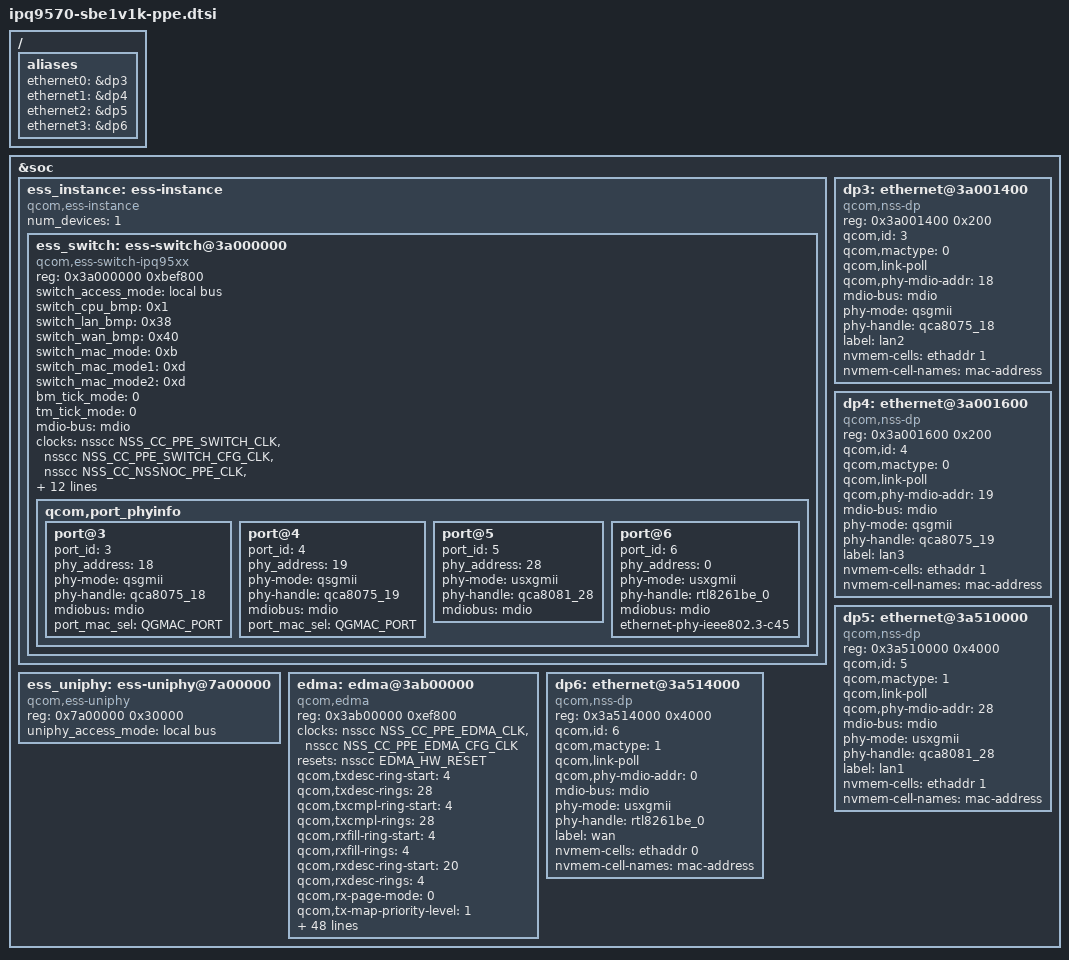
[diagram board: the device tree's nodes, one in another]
// SPDX-License-Identifier: (GPL-2.0+ OR BSD-3-Clause)
/*
 * Qualcomm QSDK14 SSDK/NSS-DP/PPE data path for the Askey SBE1V1K.
 *
 * This is intentionally separate from the board DTS so the upstream PPE
 * data path remains easy to restore while the vendor acceleration stack is
 * being validated on hardware.
 */

/ {
	aliases {
		ethernet0 = &dp3;
		ethernet1 = &dp4;
		ethernet2 = &dp5;
		ethernet3 = &dp6;
	};
};

&soc {
		ess_instance: ess-instance {
			compatible = "qcom,ess-instance";
			num_devices = <1>;
			#address-cells = <1>;
			#size-cells = <1>;

			ess_switch: ess-switch@3a000000 {
				compatible = "qcom,ess-switch-ipq95xx";
				reg = <0x3a000000 0xbef800>;
				switch_access_mode = "local bus";
				switch_cpu_bmp = <0x1>;
				switch_lan_bmp = <0x38>;
				switch_wan_bmp = <0x40>;
				switch_mac_mode = <0xb>;
				switch_mac_mode1 = <0xd>;
				switch_mac_mode2 = <0xd>;
				bm_tick_mode = <0>;
				tm_tick_mode = <0>;
				mdio-bus = <&mdio>;

				clocks = <&nsscc NSS_CC_PPE_SWITCH_CLK>,
					 <&nsscc NSS_CC_PPE_SWITCH_CFG_CLK>,
					 <&nsscc NSS_CC_NSSNOC_PPE_CLK>,
					 <&nsscc NSS_CC_NSSNOC_PPE_CFG_CLK>,
					 <&nsscc NSS_CC_PPE_EDMA_CLK>,
					 <&nsscc NSS_CC_PPE_EDMA_CFG_CLK>,
					 <&nsscc NSS_CC_PPE_SWITCH_IPE_CLK>,
					 <&nsscc NSS_CC_PPE_SWITCH_BTQ_CLK>,
					 <&nsscc NSS_CC_PORT1_MAC_CLK>,
					 <&nsscc NSS_CC_PORT2_MAC_CLK>,
					 <&nsscc NSS_CC_PORT3_MAC_CLK>,
					 <&nsscc NSS_CC_PORT4_MAC_CLK>,
					 <&nsscc NSS_CC_PORT5_MAC_CLK>,
					 <&nsscc NSS_CC_PORT6_MAC_CLK>;
				clock-names = "nss_ppe_clk",
					      "nss_ppe_cfg_clk",
					      "nssnoc_ppe_clk",
					      "nssnoc_ppe_cfg_clk",
					      "nss_edma_clk",
					      "nss_edma_cfg_clk",
					      "nss_ppe_ipe_clk",
					      "nss_ppe_btq_clk",
					      "port1_mac_clk",
					      "port2_mac_clk",
					      "port3_mac_clk",
					      "port4_mac_clk",
					      "port5_mac_clk",
					      "port6_mac_clk";
				resets = <&nsscc PPE_FULL_RESET>;
				reset-names = "ppe_rst";

				qcom,port_phyinfo {
					port@3 {
						port_id = <3>;
						phy_address = <18>;
						phy-mode = "qsgmii";
						phy-handle = <&qca8075_18>;
						mdiobus = <&mdio>;
						port_mac_sel = "QGMAC_PORT";
					};

					port@4 {
						port_id = <4>;
						phy_address = <19>;
						phy-mode = "qsgmii";
						phy-handle = <&qca8075_19>;
						mdiobus = <&mdio>;
						port_mac_sel = "QGMAC_PORT";
					};

					port@5 {
						port_id = <5>;
						phy_address = <28>;
						phy-mode = "usxgmii";
						phy-handle = <&qca8081_28>;
						mdiobus = <&mdio>;
					};

					port@6 {
						port_id = <6>;
						phy_address = <0>;
						phy-mode = "usxgmii";
						phy-handle = <&rtl8261be_0>;
						mdiobus = <&mdio>;
						ethernet-phy-ieee802.3-c45;
					};
				};
			};
		};

		ess_uniphy: ess-uniphy@7a00000 {
			compatible = "qcom,ess-uniphy";
			reg = <0x7a00000 0x30000>;
			uniphy_access_mode = "local bus";
		};

		edma: edma@3ab00000 {
			compatible = "qcom,edma";
			reg = <0x3ab00000 0xef800>;
			reg-names = "edma-reg-base";

			clocks = <&nsscc NSS_CC_PPE_EDMA_CLK>,
				 <&nsscc NSS_CC_PPE_EDMA_CFG_CLK>;
			clock-names = "nss-edma-clk",
				      "nss-edma-cfg-clk";
			resets = <&nsscc EDMA_HW_RESET>;
			reset-names = "edma_rst";

			qcom,txdesc-ring-start = <4>;
			qcom,txdesc-rings = <28>;
			qcom,txcmpl-ring-start = <4>;
			qcom,txcmpl-rings = <28>;
			qcom,rxfill-ring-start = <4>;
			qcom,rxfill-rings = <4>;
			qcom,rxdesc-ring-start = <20>;
			qcom,rxdesc-rings = <4>;
			qcom,rx-page-mode = <0>;
			qcom,tx-map-priority-level = <1>;
			qcom,rx-map-priority-level = <1>;
			qcom,txdesc-map = <8 9 10 11>,
					  <12 13 14 15>,
					  <16 17 18 19>,
					  <20 21 22 23>,
					  <24 25 26 27>,
					  <28 29 30 31>,
					  <4 5 6 7>;
			qcom,txdesc-fc-grp-map = <1 2 3 4 5 6>;
			qcom,rxfill-map = <4 5 6 7>;
			qcom,rxdesc-map = <20 21 22 23>;
			qcom,rx-ring-queue-map = <0 8 16 24>,
						 <1 9 17 25>,
						 <2 10 18 26>,
						 <3 11 19 27>,
						 <4 12 20 28>,
						 <5 13 21 29>,
						 <6 14 22 30>,
						 <7 15 23 31>;
			qcom,vp-id = <8>;

			interrupts = <GIC_SPI 367 IRQ_TYPE_LEVEL_HIGH>,
				     <GIC_SPI 368 IRQ_TYPE_LEVEL_HIGH>,
				     <GIC_SPI 369 IRQ_TYPE_LEVEL_HIGH>,
				     <GIC_SPI 370 IRQ_TYPE_LEVEL_HIGH>,
				     <GIC_SPI 371 IRQ_TYPE_LEVEL_HIGH>,
				     <GIC_SPI 372 IRQ_TYPE_LEVEL_HIGH>,
				     <GIC_SPI 373 IRQ_TYPE_LEVEL_HIGH>,
				     <GIC_SPI 374 IRQ_TYPE_LEVEL_HIGH>,
				     <GIC_SPI 375 IRQ_TYPE_LEVEL_HIGH>,
				     <GIC_SPI 376 IRQ_TYPE_LEVEL_HIGH>,
				     <GIC_SPI 377 IRQ_TYPE_LEVEL_HIGH>,
				     <GIC_SPI 378 IRQ_TYPE_LEVEL_HIGH>,
				     <GIC_SPI 379 IRQ_TYPE_LEVEL_HIGH>,
				     <GIC_SPI 380 IRQ_TYPE_LEVEL_HIGH>,
				     <GIC_SPI 381 IRQ_TYPE_LEVEL_HIGH>,
				     <GIC_SPI 382 IRQ_TYPE_LEVEL_HIGH>,
				     <GIC_SPI 383 IRQ_TYPE_LEVEL_HIGH>,
				     <GIC_SPI 384 IRQ_TYPE_LEVEL_HIGH>,
				     <GIC_SPI 509 IRQ_TYPE_LEVEL_HIGH>,
				     <GIC_SPI 508 IRQ_TYPE_LEVEL_HIGH>,
				     <GIC_SPI 507 IRQ_TYPE_LEVEL_HIGH>,
				     <GIC_SPI 506 IRQ_TYPE_LEVEL_HIGH>,
				     <GIC_SPI 505 IRQ_TYPE_LEVEL_HIGH>,
				     <GIC_SPI 504 IRQ_TYPE_LEVEL_HIGH>,
				     <GIC_SPI 503 IRQ_TYPE_LEVEL_HIGH>,
				     <GIC_SPI 502 IRQ_TYPE_LEVEL_HIGH>,
				     <GIC_SPI 501 IRQ_TYPE_LEVEL_HIGH>,
				     <GIC_SPI 500 IRQ_TYPE_LEVEL_HIGH>,
				     <GIC_SPI 351 IRQ_TYPE_LEVEL_HIGH>,
				     <GIC_SPI 352 IRQ_TYPE_LEVEL_HIGH>,
				     <GIC_SPI 353 IRQ_TYPE_LEVEL_HIGH>,
				     <GIC_SPI 354 IRQ_TYPE_LEVEL_HIGH>,
				     <GIC_SPI 499 IRQ_TYPE_LEVEL_HIGH>,
				     <GIC_SPI 359 IRQ_TYPE_LEVEL_HIGH>,
				     <GIC_SPI 360 IRQ_TYPE_LEVEL_HIGH>,
				     <GIC_SPI 361 IRQ_TYPE_LEVEL_HIGH>,
				     <GIC_SPI 362 IRQ_TYPE_LEVEL_HIGH>;
		};

		dp3: ethernet@3a001400 {
			compatible = "qcom,nss-dp";
			reg = <0x3a001400 0x200>;
			qcom,id = <3>;
			qcom,mactype = <0>;
			qcom,link-poll;
			qcom,phy-mdio-addr = <18>;
			mdio-bus = <&mdio>;
			phy-mode = "qsgmii";
			phy-handle = <&qca8075_18>;
			label = "lan2";
			nvmem-cells = <&ethaddr 1>;
			nvmem-cell-names = "mac-address";
		};

		dp4: ethernet@3a001600 {
			compatible = "qcom,nss-dp";
			reg = <0x3a001600 0x200>;
			qcom,id = <4>;
			qcom,mactype = <0>;
			qcom,link-poll;
			qcom,phy-mdio-addr = <19>;
			mdio-bus = <&mdio>;
			phy-mode = "qsgmii";
			phy-handle = <&qca8075_19>;
			label = "lan3";
			nvmem-cells = <&ethaddr 1>;
			nvmem-cell-names = "mac-address";
		};

		dp5: ethernet@3a510000 {
			compatible = "qcom,nss-dp";
			reg = <0x3a510000 0x4000>;
			qcom,id = <5>;
			qcom,mactype = <1>;
			qcom,link-poll;
			qcom,phy-mdio-addr = <28>;
			mdio-bus = <&mdio>;
			phy-mode = "usxgmii";
			phy-handle = <&qca8081_28>;
			label = "lan1";
			nvmem-cells = <&ethaddr 1>;
			nvmem-cell-names = "mac-address";
		};

		dp6: ethernet@3a514000 {
			compatible = "qcom,nss-dp";
			reg = <0x3a514000 0x4000>;
			qcom,id = <6>;
			qcom,mactype = <1>;
			qcom,link-poll;
			qcom,phy-mdio-addr = <0>;
			mdio-bus = <&mdio>;
			phy-mode = "usxgmii";
			phy-handle = <&rtl8261be_0>;
			label = "wan";
			nvmem-cells = <&ethaddr 0>;
			nvmem-cell-names = "mac-address";
		};
};
